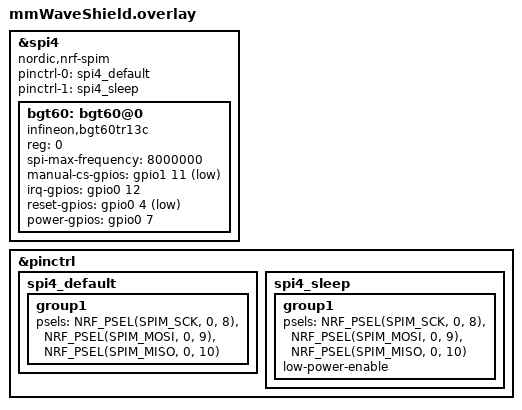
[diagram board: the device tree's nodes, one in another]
/*
 * Copyright (c) 2022 Nordic Semiconductor ASA
 *
 * SPDX-License-Identifier: LicenseRef-Nordic-5-Clause
 */


//&i2c0 {	status = "disabled";};
//&spi0 {	status = "disabled";};
//&i2c1 {	status = "disabled";};


&spi4 {
    compatible = "nordic,nrf-spim";
    status = "okay";
    pinctrl-0 = <&spi4_default>;
    pinctrl-1 = <&spi4_sleep>;
    pinctrl-names = "default", "sleep";
    bgt60: bgt60@0 {
        compatible = "infineon,bgt60tr13c";
        reg = <0>;
        spi-max-frequency = <8000000>; 
        manual-cs-gpios = <&gpio1 11 GPIO_ACTIVE_LOW>;
        irq-gpios = <&gpio0 12 GPIO_ACTIVE_HIGH>;
        reset-gpios = <&gpio0 4 GPIO_ACTIVE_LOW>;
        power-gpios = <&gpio0 7 GPIO_ACTIVE_HIGH>;
    };
};


&pinctrl {
    spi4_default: spi4_default {
        group1 {
            psels = <NRF_PSEL(SPIM_SCK, 0, 8)>,					 
                    <NRF_PSEL(SPIM_MOSI, 0, 9)>,
                    <NRF_PSEL(SPIM_MISO, 0, 10)>;
        };
    };
    spi4_sleep: spi4_sleep {
        group1 {
            psels = <NRF_PSEL(SPIM_SCK, 0, 8)>,
                    <NRF_PSEL(SPIM_MOSI, 0, 9)>,
                    <NRF_PSEL(SPIM_MISO, 0, 10)>;
            low-power-enable;
        };
    };
};

